# ATtiny840 device description
Architecture: AVR8; Family: tinyAVR
Registers are 8-bit, access not given, no defined reset value unless marked. A register's access mark holds for its fields unless they carry their own. Offsets are from the block's base; [hi:lo] are bit positions; {n}, {i} and the like mark numbered series.

## LOCKBIT — Lockbits
Instances: LOCKBIT 0 in lockbits
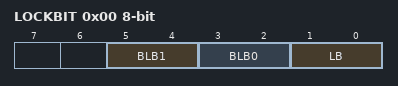
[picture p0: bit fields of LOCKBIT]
0x00 LOCKBIT
  [5:4] BLB1 — Boot Loader Protection Mode
    0=LPM_SPM_DISABLE (LPM and SPM prohibited in Boot Section); 1=LPM_DISABLE (LPM prohibited in Boot Section); 2=SPM_DISABLE (SPM prohibited in Boot Section); 3=NO_LOCK (No lock on SPM and LPM in Boot Section)
  [3:2] BLB0 — Boot Loader Protection Mode
    0=LPM_SPM_DISABLE (LPM and SPM prohibited in Application Section); 1=LPM_DISABLE (LPM prohibited in Application Section); 2=SPM_DISABLE (SPM prohibited in Application Section); 3=NO_LOCK (No lock on SPM and LPM in Application Section)
  [1:0] LB — Memory Lock
    0=PROG_VER_DISABLED (Further programming and verification disabled); 2=PROG_DISABLED (Further programming disabled); 3=NO_LOCK (No memory lock features enabled)

## DEVICEID
Instances: DEVICEID 0x0
{0xF0+i} DEVID{i} (i=0..8)

## USART1 — USART
Instances: USART1 0x00
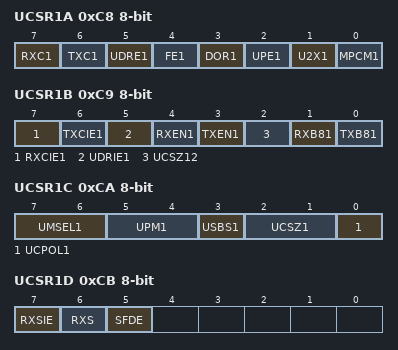
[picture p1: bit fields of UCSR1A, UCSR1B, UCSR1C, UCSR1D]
0xC8 UCSR1A — USART Control and Status Register A
  [7] RXC1 — USART Receive Complete
  [6] TXC1 — USART Transmitt Complete
  [5] UDRE1 — USART Data Register Empty
  [4] FE1 — Framing Error
  [3] DOR1 — Data overRun
  [2] UPE1 — Parity Error
  [1] U2X1 — Double the USART transmission speed
  [0] MPCM1 — Multi-processor Communication Mode
0xC9 UCSR1B — USART Control and Status Register B
  [7] RXCIE1 — RX Complete Interrupt Enable
  [6] TXCIE1 — TX Complete Interrupt Enable
  [5] UDRIE1 — USART Data register Empty Interrupt Enable
  [4] RXEN1 — Receiver Enable
  [3] TXEN1 — Transmitter Enable
  [2] UCSZ12 — Character Size
  [1] RXB81 — Receive Data Bit 8
  [0] TXB81 — Transmit Data Bit 8
0xCA UCSR1C — USART Control and Status Register C
  [7:6] UMSEL1 — USART Mode Select
    0=Asynchronous USART; 1=Synchronous USART; 3=Master SPI
  [5:4] UPM1 — Parity Mode Bits
    0=Disabled; 2=Enabled, Even Parity; 3=Enabled, Odd Parity
  [3] USBS1 — Stop Bit Select
    0=1-bit; 1=2-bit
  [2:1] UCSZ1 — Character Size
  [0] UCPOL1 — Clock Polarity
0xCB UCSR1D — USART Control and Status Register D
  [7] RXSIE — RX Start Interrupt Enable
  [6] RXS — RX Start
  [5] SFDE — Start Frame Detection Enable
0xCC UBRR1 16-bit bits used 11:0 — USART Baud Rate Register Bytes
0xCE UDR1 — USART I/O Data Register

## TC1 (TC16 module) — Timer/Counter, 16-bit
Instances: TC1 0x00
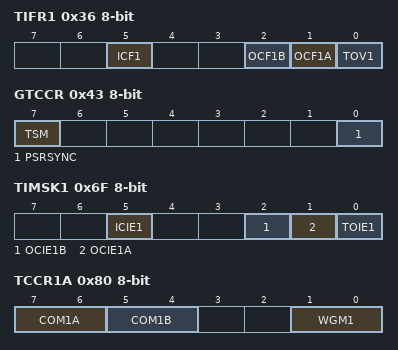
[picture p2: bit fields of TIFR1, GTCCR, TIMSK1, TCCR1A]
0x36 TIFR1 — Timer/Counter Interrupt Flag register
  [5] ICF1 — Input Capture Flag 1
  [2] OCF1B — Output Compare Flag 1B
  [1] OCF1A — Output Compare Flag 1A
  [0] TOV1 — Timer/Counter1 Overflow Flag
0x43 GTCCR — General Timer/Counter Control Register
  [7] TSM — Timer/Counter Synchronization Mode
  [0] PSRSYNC — Prescaler Reset Timer/Counter1 and Timer/Counter0
0x6F TIMSK1 — Timer/Counter1 Interrupt Mask Register
  [5] ICIE1 — Timer/Counter1 Input Capture Interrupt Enable
  [2] OCIE1B — Timer/Counter1 Output CompareB Match Interrupt Enable
  [1] OCIE1A — Timer/Counter1 Output CompareA Match Interrupt Enable
  [0] TOIE1 — Timer/Counter1 Overflow Interrupt Enable
0x80 TCCR1A — Timer/Counter1 Control Register A
  [7:6] COM1A — Compare Output Mode 1A, bits
  [5:4] COM1B — Compare Output Mode 1B, bits
  [1:0] WGM1 — Waveform Generation Mode
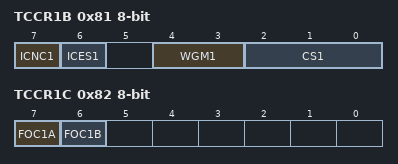
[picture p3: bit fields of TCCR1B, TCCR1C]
0x81 TCCR1B — Timer/Counter1 Control Register B
  [7] ICNC1 — Input Capture 1 Noise Canceler
  [6] ICES1 — Input Capture 1 Edge Select
  [4:3] WGM1 (bit 2 of the value upward) — Waveform Generation Mode
  [2:0] CS1 — Prescaler source of Timer/Counter 1
    0=No Clock Source (Stopped); 1=Running, No Prescaling; 2=Running, CLK/8; 3=Running, CLK/64; 4=Running, CLK/256; 5=Running, CLK/1024; 6=Running, ExtClk Tx Falling Edge; 7=Running, ExtClk Tx Rising Edge
0x82 TCCR1C — Timer/Counter1 Control Register C
  [7] FOC1A, [6] FOC1B
0x84 TCNT1 16-bit — Timer/Counter1 Bytes
0x86 ICR1 16-bit — Timer/Counter1 Input Capture Register Bytes
0x88 OCR1A 16-bit — Timer/Counter1 Output Compare Register Bytes
0x8A OCR1B 16-bit — Timer/Counter1 Output Compare Register Bytes
